# BOOT_CFG register map
Vendor: Texas Instruments
Peripheral module from a debugger description file (folder 66AK2G0x_66AK2G1x).
Registers are 32-bit, access per field, no defined reset value unless marked. A register's access mark holds for its fields unless they carry their own. Offsets are as the file gives them; lines under a group give offsets from that group; [hi:lo] are bit positions; {n}, {i} and the like mark numbered series; 'fields as' and 'values as' point back to an identical list; <NAME> marks a mode.

## BOOT_CFG
0x00 BOOTCFG_REVISION ro reset 0x4E842901
  [31:0] BOOTCFG_REV — TI internal data. Identifies revision of peripheral.
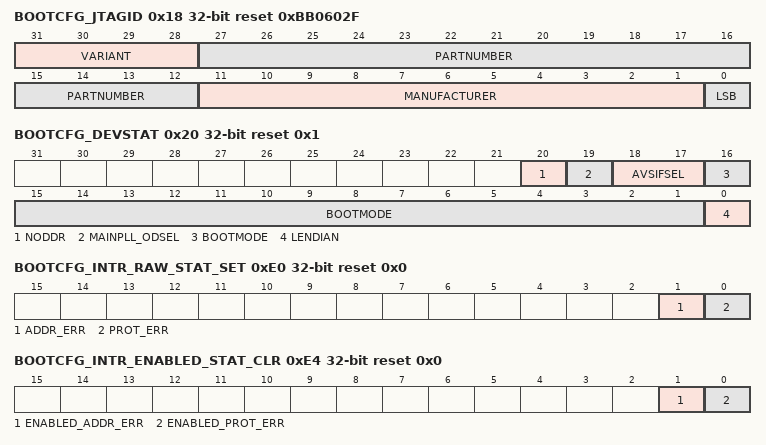
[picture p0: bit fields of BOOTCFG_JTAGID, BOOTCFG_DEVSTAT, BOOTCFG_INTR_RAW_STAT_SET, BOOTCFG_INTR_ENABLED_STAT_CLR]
0x18 BOOTCFG_JTAGID ro reset 0xBB0602F (reset mask 0xFFFFFFF)
  [31:28] VARIANT — Variant value1h for 66AK2G0x devices8h for 66AK2G1x devices
  [27:12] PARTNUMBER — Part number for boundary scan
  [11:1] MANUFACTURER — Indicates manufacture
  [0] LSB
0x20 BOOTCFG_DEVSTAT reset 0x1
  [20] NODDR ro — MSMC to EMIF control 0 - EMIF enabled, MSMC sends external traffic to DDR(normal mode) 1 - EMIF disabled, MSMC will re-direct DDR traffic toMSMC internal null end point
  [19] MAINPLL_ODSEL rw — Main PLL OUTPUT_DIVIDE (OD) selection for the Boot ROM code.
  [18:17] AVSIFSEL rw — Reserved
  [16:1] BOOTMODE rw — Boot mode selection
  [0] LENDIAN ro — Device Endian Mode. Applies to the entire device.
0x38 BOOTCFG_KICK0 rw reset 0x0
0x3C BOOTCFG_KICK1 rw reset 0x0
0x40 BOOTCFG_DSP_BOOT_ADDR0 reset 0x20B00000
  [31:10] ISTP_RST_VAL rw — DSP istp_rst_val[21:0] port value. On secure device this field is read-only by Secure Master. Emulator cannot access this in Secure mode.
0xE0 BOOTCFG_INTR_RAW_STAT_SET access not given reset 0x0
  [1] ADDR_ERR — Addressing violation error. Raw status is read. Write a 1 to set the status. Writing a 0 has no effect. (access W1toS)
  [0] PROT_ERR — Protection violation error. Raw status is read. Write a 1 to set the status. Writing a 0 has no effect. (access W1toS)
0xE4 BOOTCFG_INTR_ENABLED_STAT_CLR access not given reset 0x0
  [1] ENABLED_ADDR_ERR — Addressing violation error. Enabled status is read. Write a 1 to clear the status. Writing a 0 has no effect. (access W1toCl)
  [0] ENABLED_PROT_ERR — Protection violation error. Enabled status is read. Write a 1 to clear the status. Writing a 0 has no effect. (access W1toCl)
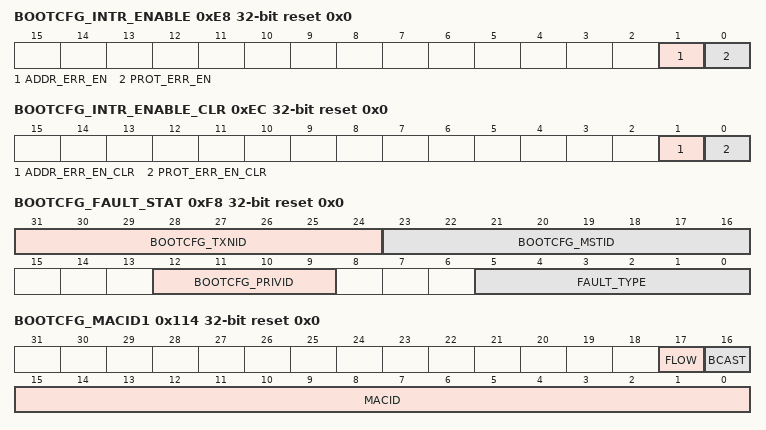
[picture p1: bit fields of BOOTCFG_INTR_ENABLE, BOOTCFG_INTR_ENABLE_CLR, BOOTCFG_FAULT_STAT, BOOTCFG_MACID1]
0xE8 BOOTCFG_INTR_ENABLE access not given reset 0x0
  [1] ADDR_ERR_EN — Addressing violation error enable. Write a 1 to set the enable. Writing a 0 has no effect. (access W1toS)
  [0] PROT_ERR_EN — Protection violation error enable. Write a 1 to set the enable. Writing a 0 has no effect. (access W1toS)
0xEC BOOTCFG_INTR_ENABLE_CLR access not given reset 0x0
  [1] ADDR_ERR_EN_CLR — Addressing violation error enable. Write a 1 to clear the enable. Writing a 0 has no effect. (access W1toCl)
  [0] PROT_ERR_EN_CLR — Protection violation error enable. Write a 1 to clear the enable. Writing a 0 has no effect. (access W1toCl)
0xF0 BOOTCFG_EOI reset 0x0
  [7:0] EOI_VECTOR rw — EOI vector value.
0xF4 BOOTCFG_FAULT_ADDR ro reset 0x0
  [31:0] FAULT_ADDR — Fault address.
0xF8 BOOTCFG_FAULT_STAT ro reset 0x0
  [31:24] BOOTCFG_TXNID — Transaction ID associated with the fault access
  [23:16] BOOTCFG_MSTID — Master ID associated with the fault access
  [12:9] BOOTCFG_PRIVID — Privilege ID associated with the fault access
  [5:0] FAULT_TYPE — Fault type. 000000b = no fault 000001b = user execute fault 000010b = user write fault 000100b = user read fault 001000b = supervisor execute fault 010000b = supervisor write fault 100000b = supervisor read fault
0xFC BOOTCFG_FAULT_CLR access not given reset 0x0
  [0] FAULT_CLR — Fault clear. Writing a 1 clears the current fault. Writing a 0 has no effect. (access W1toCl)
0x110 BOOTCFG_MACID0 ro
  [31:0] MACID — MAC ID, lower 32 bits
0x114 BOOTCFG_MACID1 ro reset 0x0 (reset mask 0xFFFF0000)
  [17] FLOW — MAC Flow Control
  [16] BCAST — Default m/b-cast reception
  [15:0] MACID — MAC ID, upper 16 bits
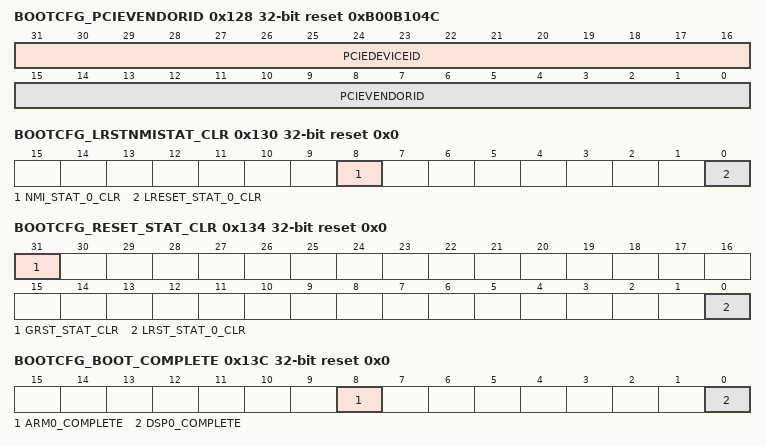
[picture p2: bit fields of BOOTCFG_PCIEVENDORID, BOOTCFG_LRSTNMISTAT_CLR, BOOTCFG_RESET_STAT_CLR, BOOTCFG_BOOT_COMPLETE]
0x128 BOOTCFG_PCIEVENDORID rw reset 0xB00B104C
  [31:16] PCIEDEVICEID
  [15:0] PCIEVENDORID — TI Vendor ID
0x130 BOOTCFG_LRSTNMISTAT_CLR access not given reset 0x0
  [8] NMI_STAT_0_CLR — C66x core 0 NMI pin clear (access RWtoPH)
  [0] LRESET_STAT_0_CLR — C66x core 0 local reset pin clear (access RWtoPH)
0x134 BOOTCFG_RESET_STAT_CLR access not given reset 0x0
  [31] GRST_STAT_CLR — Global reset clear (access RWtoPH)
  [0] LRST_STAT_0_CLR — C66x core 0 local reset clear (access RWtoPH)
0x13C BOOTCFG_BOOT_COMPLETE access not given reset 0x0
  [8] ARM0_COMPLETE — A15 core 0 ROM boot status (access RW1toS)
  [0] DSP0_COMPLETE — C66x core 0 ROM boot status (access RW1toS)
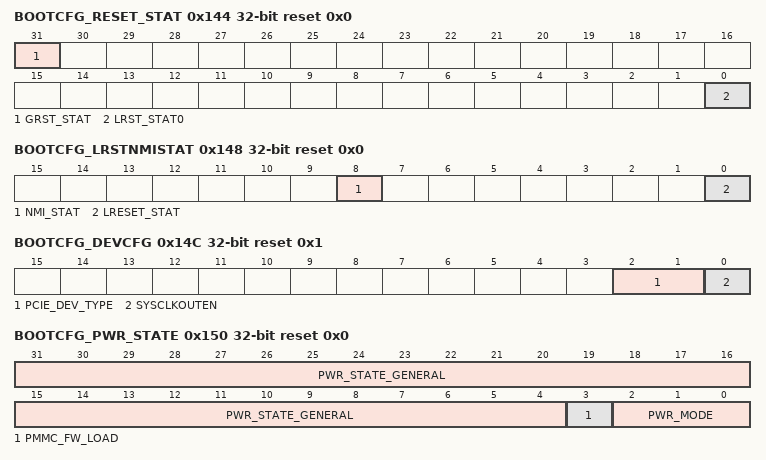
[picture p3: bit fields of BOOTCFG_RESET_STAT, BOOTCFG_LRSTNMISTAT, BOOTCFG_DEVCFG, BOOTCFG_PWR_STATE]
0x144 BOOTCFG_RESET_STAT ro reset 0x0
  [31] GRST_STAT — Global reset status
  [0] LRST_STAT0 — C66x core 0 local reset status
0x148 BOOTCFG_LRSTNMISTAT ro reset 0x0
  [8] NMI_STAT — C66x core 0 NMI pin status
  [0] LRESET_STAT — C66x core 0 local reset pin status
0x14C BOOTCFG_DEVCFG reset 0x1
  [2:1] PCIE_DEV_TYPE rw — PCIE device type 0h = Endpoint mode 1h = Legacy Endpoint mode 2h = Rootcomplex mode
  [0] SYSCLKOUTEN rw — SYSCLKOUT enable
0x150 BOOTCFG_PWR_STATE rw reset 0x0
  [31:4] PWR_STATE_GENERAL — General purpose register, allocated for software usage
  [3] PMMC_FW_LOAD — Indicates whether PMMC firmware is loaded by host processor (A15 or DSP) or not
  [2:0] PWR_MODE — Indicates device power mode
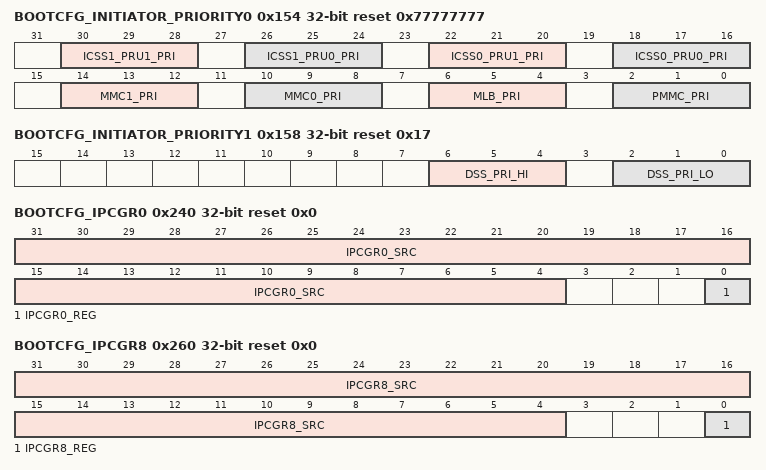
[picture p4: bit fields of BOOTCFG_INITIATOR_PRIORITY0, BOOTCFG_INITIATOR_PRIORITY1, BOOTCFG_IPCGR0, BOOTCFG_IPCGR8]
0x154 BOOTCFG_INITIATOR_PRIORITY0 reset 0x77777777
  [30:28] ICSS1_PRU1_PRI rw — ICSS1 PRU1 master port priority
  [26:24] ICSS1_PRU0_PRI rw — ICSS1 PRU0 master port priority
  [22:20] ICSS0_PRU1_PRI rw — ICSS0 PRU1 master port priority
  [18:16] ICSS0_PRU0_PRI rw — ICSS0 PRU0 master port priority
  [14:12] MMC1_PRI rw — MMC1 master port priority
  [10:8] MMC0_PRI rw — MMC0 master port priority
  [6:4] MLB_PRI rw — MLB master port priority
  [2:0] PMMC_PRI rw — PMMC master port priority
0x158 BOOTCFG_INITIATOR_PRIORITY1 reset 0x17
  [6:4] DSS_PRI_HI rw — DSS master port priority for high priority access (when MFLAG = 1)
  [2:0] DSS_PRI_LO rw — DSS master port priority for low priority access (when MFLAG = 0)
0x200 BOOTCFG_NMIGR0 access not given reset 0x0
  [0] NMIGR0_REG — Reads return 0 (access RWtoPH)
0x240 BOOTCFG_IPCGR0 access not given reset 0x0
  [31:4] IPCGR0_SRC — Reads return current value of internal register bit (access RW1toS)
  [0] IPCGR0_REG — Reads return 0 (access RWtoPH)
0x260 BOOTCFG_IPCGR8 access not given reset 0x0
  [31:4] IPCGR8_SRC — Reads return current value of internal register bit (access RW1toS)
  [0] IPCGR8_REG — Reads return 0 (access RWtoPH)
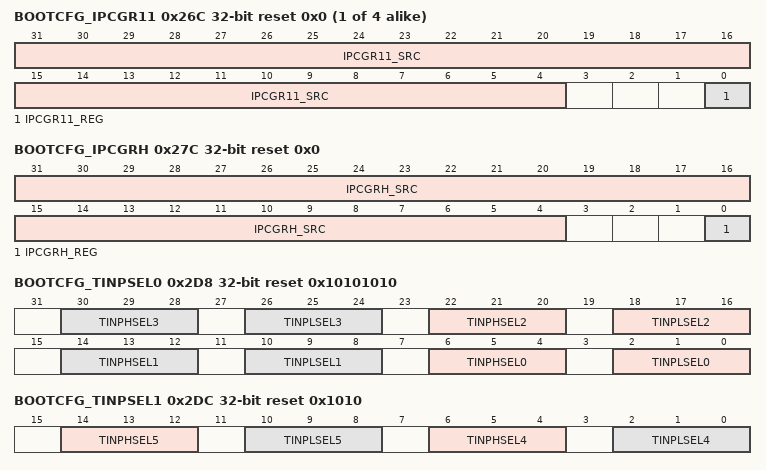
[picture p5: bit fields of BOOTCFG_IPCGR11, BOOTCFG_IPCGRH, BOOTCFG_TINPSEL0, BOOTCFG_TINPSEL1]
{0x240+4i} BOOTCFG_IPCGR{i} access not given reset 0x0 (i=11..14)
  [31:4] IPCGR{i}_SRC — Reads return current value of internal register bit (access RW1toS)
  [0] IPCGR{i}_REG — Reads return 0 (access RWtoPH)
0x27C BOOTCFG_IPCGRH access not given reset 0x0
  [31:4] IPCGRH_SRC — Reads return current value of internal register bit (access RW1toS)
  [0] IPCGRH_REG — Reads return 0 (access RWtoPH)
0x280 BOOTCFG_IPCAR0 access not given reset 0x0
  [31:4] IPCGR0_SRC_CLR — Reads return current value of internal register bit (access RW1toCl)
0x2A0 BOOTCFG_IPCAR8 access not given reset 0x0
  [31:4] IPCGR8_SRC_CLR — Reads return current value of internal register bit (access RW1toCl)
{0x280+4i} BOOTCFG_IPCAR{i} access not given reset 0x0 (i=11..14)
  [31:4] IPCGR{i}_SRC_CLR — Reads return current value of internal register bit (access RW1toC)
0x2BC BOOTCFG_IPCARH access not given reset 0x0
  [31:4] IPCGRH_SRC_CLR — Reads return current value of internal register bit (access RW1toC)
0x2D8 BOOTCFG_TINPSEL0 reset 0x10101010
  [8n+6:8n+4] TINPHSEL{n} rw (n=0..3) — Input select for TIMER_{n} high 0h = TIMI0 1h = TIMI1
  [8n+2:8n] TINPLSEL{n} rw (n=0..3) — Input select for TIMER_{n} low 0h = TIMI0 1h = TIMI1
0x2DC BOOTCFG_TINPSEL1 reset 0x1010
  [14:12] TINPHSEL5 rw — Input select for TIMER_5 high 0h = TIMI0 1h = TIMI1
  [10:8] TINPLSEL5 rw — Input select for TIMER_5 low 0h = TIMI0 1h = TIMI1
  [6:4] TINPHSEL4 rw — Input select for TIMER_4 high 0h = TIMI0 1h = TIMI1
  [2:0] TINPLSEL4 rw — Input select for TIMER_4 low 0h = TIMI0 1h = TIMI1
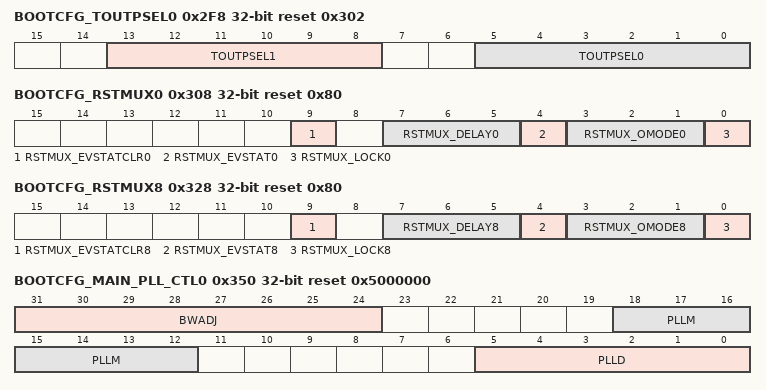
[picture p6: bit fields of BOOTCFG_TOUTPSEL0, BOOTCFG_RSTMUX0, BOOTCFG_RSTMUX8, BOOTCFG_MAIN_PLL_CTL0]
0x2F8 BOOTCFG_TOUTPSEL0 reset 0x302
  [13:8] TOUTPSEL1 rw — Output select for TIMO1 0h = TOUTL0 1h = TOUTH0 2h = TOUTL1 3h = TOUTH1 4h = TOUTL2 5h = TOUTH2 6h = TOUTL3 7h = TOUTH3 8h = TOUTL4 9h = TOUTH4 Ah = TOUTL5 Bh = TOUTH5
  [5:0] TOUTPSEL0 rw — Output select for TIMO0 0h = TOUTL0 1h = TOUTH0 2h = TOUTL1 3h = TOUTH1 4h = TOUTL2 5h = TOUTH2 6h = TOUTL3 7h = TOUTH3 8h = TOUTL4 9h = TOUTH4 Ah = TOUTL5 Bh = TOUTH5
0x308 BOOTCFG_RSTMUX0 access not given reset 0x80
  [9] RSTMUX_EVSTATCLR0 — Clear event status (access RWtoPH)
  [7:5] RSTMUX_DELAY0 rw — Delay cycles between NMI and local reset to C66x core incase of C66x WD timer, or delay between GIC interrupt and device reset in case of A15 WD timer
  [4] RSTMUX_EVSTAT0 ro — Event status
  [3:1] RSTMUX_OMODE0 rw — Watchdog timer event operation mode
  [0] RSTMUX_LOCK0 rw — Lock register fields
0x328 BOOTCFG_RSTMUX8 access not given reset 0x80
  [9] RSTMUX_EVSTATCLR8 — Clear event status (access RWtoPH)
  [7:5] RSTMUX_DELAY8 rw — Delay cycles between NMI and local reset to C66x core incase of C66x WD timer, or delay between GIC interrupt and device reset in case of A15 WD timer
  [4] RSTMUX_EVSTAT8 ro — Event status
  [3:1] RSTMUX_OMODE8 rw — Watchdog timer event operation mode
  [0] RSTMUX_LOCK8 rw — Lock register fields
0x350 BOOTCFG_MAIN_PLL_CTL0 reset 0x5000000
  [31:24] BWADJ rw — 8-bit LSB of a 12-bit BWADJ field that selects the values for the loop bandwidth adjustment. BWADJ[7-0] is controlled from this register and BWADJ[11-8] is controlled from
  [18:12] PLLM rw — 7-bit MSB of a 13-bit PLLM field that selects the values for the multiplication factor. PLLM field is loaded with the multiply factor minus 1. The PLLM[5-0] bits of the multiplier are controlled by the PLLM register inside the PLL Controller and the PLLM[12-6] bits are controlled by this register. This field should be written just before writing to PLLM[5-0] bits of the PLLM register to have the complete 13-bit value latched when the GO operation is initiated in the PLL Controller
  [5:0] PLLD rw — A 6-bit field that selects the values for the reference divider. PLLD field is loaded with reference divider value minus 1
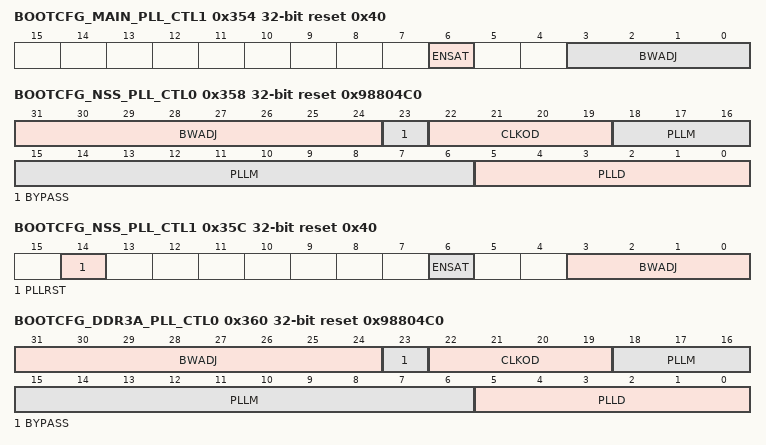
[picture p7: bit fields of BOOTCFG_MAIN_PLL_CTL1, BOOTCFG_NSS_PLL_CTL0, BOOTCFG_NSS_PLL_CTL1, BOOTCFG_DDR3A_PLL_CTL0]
0x354 BOOTCFG_MAIN_PLL_CTL1 reset 0x40
  [6] ENSAT rw — Enables saturation behavior, needs to be set to 1 for proper PLLoperation
  [3:0] BWADJ rw — 4-bit MSB of a 12-bit BWADJ field that selects the values for the loop bandwidth adjustment. BWADJ[7-0] is controlled from MAINPLLCTL0 register and BWADJ[11-8] is controlled from this register. BWADJ[11-0] should be programmed to a value equal to half of PLLM[12-0] value (round down if PLLM has an odd value).
0x358 BOOTCFG_NSS_PLL_CTL0 rw reset 0x98804C0
  [31:24] BWADJ — 8-bit LSB of a 12-bit BWADJ field that selects the values for the loop bandwidth adjustment. BWADJ[7-0] is controlled from this register and BWADJ[11-8] is controlled from
  [23] BYPASS — Enable bypass mode
  [22:19] CLKOD — PLL output divider (post VCO), supported value = 1 (i.e. divide-by-2)
  [18:6] PLLM — A 13-bit field that selects the values for the multiplication factor. PLLM field is loaded with the multiply factor minus 1
  [5:0] PLLD — A 6-bit field that selects the values for the reference divider. PLLD field is loaded with reference divide value minus 1
0x35C BOOTCFG_NSS_PLL_CTL1 reset 0x40
  [14] PLLRST rw — PLL reset bit
  [6] ENSAT rw — Enables saturation behavior, needs to be set to 1 for proper PLL operation
  [3:0] BWADJ rw — 4-bit MSB of a 12-bit BWADJ field that selects the values for the loop bandwidth adjustment. BWADJ[7-0] is controlled from
0x360 BOOTCFG_DDR3A_PLL_CTL0 rw reset 0x98804C0
  fields as BOOTCFG_NSS_PLL_CTL0
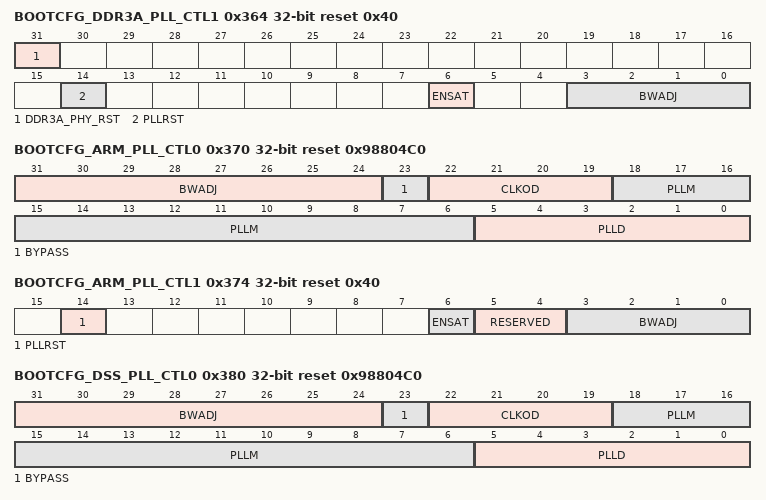
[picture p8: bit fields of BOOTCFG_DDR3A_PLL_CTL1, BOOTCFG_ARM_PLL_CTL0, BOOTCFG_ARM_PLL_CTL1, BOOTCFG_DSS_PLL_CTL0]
0x364 BOOTCFG_DDR3A_PLL_CTL1 reset 0x40
  [31] DDR3A_PHY_RST rw — DDR3 PHY reset control For more information, see
  [14] PLLRST rw — PLL reset bit
  [6] ENSAT rw — Enables saturation behavior, needs to be set to 1 for proper PLL operation
  [3:0] BWADJ rw — 4-bit MSB of a 12-bit BWADJ field that selects the values for the loop bandwidth adjustment. BWADJ[7-0] is controlled from
0x370 BOOTCFG_ARM_PLL_CTL0 rw reset 0x98804C0
  fields as BOOTCFG_NSS_PLL_CTL0
0x374 BOOTCFG_ARM_PLL_CTL1 reset 0x40
  [14] PLLRST rw — PLL reset bit
  [6] ENSAT rw — Enables saturation behavior, needs to be set to 1 for proper PLL operation
  [5:4] RESERVED ro — Enables fast locking circuit
  [3:0] BWADJ rw — 4-bit MSB of a 12-bit BWADJ field that selects the values for the loop bandwidth adjustment. BWADJ[7-0] is controlled from
0x380 BOOTCFG_DSS_PLL_CTL0 rw reset 0x98804C0
  fields as BOOTCFG_NSS_PLL_CTL0
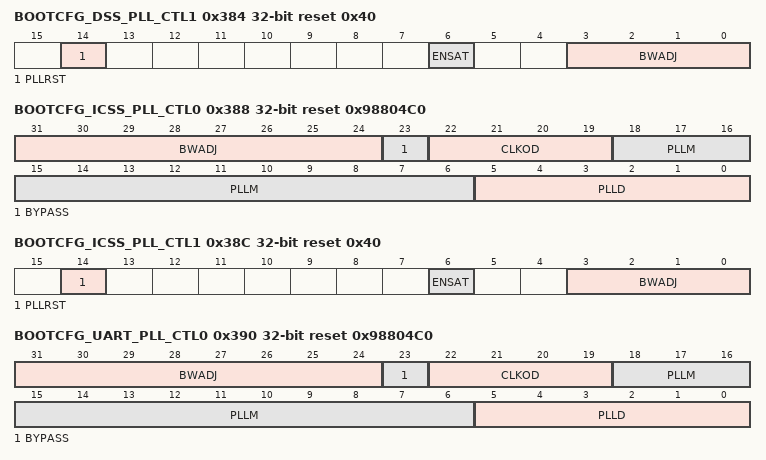
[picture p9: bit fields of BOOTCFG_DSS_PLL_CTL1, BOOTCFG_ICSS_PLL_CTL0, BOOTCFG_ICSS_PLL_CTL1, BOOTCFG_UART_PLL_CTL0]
0x384 BOOTCFG_DSS_PLL_CTL1 reset 0x40
  fields as BOOTCFG_NSS_PLL_CTL1
0x388 BOOTCFG_ICSS_PLL_CTL0 rw reset 0x98804C0
  fields as BOOTCFG_NSS_PLL_CTL0
0x38C BOOTCFG_ICSS_PLL_CTL1 reset 0x40
  fields as BOOTCFG_NSS_PLL_CTL1
0x390 BOOTCFG_UART_PLL_CTL0 rw reset 0x98804C0
  fields as BOOTCFG_NSS_PLL_CTL0
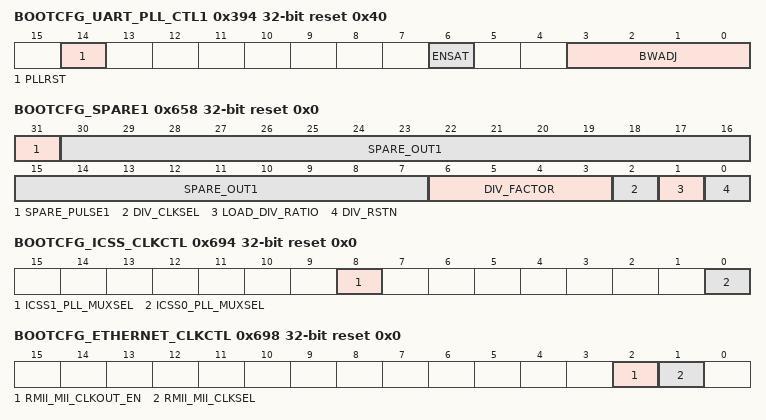
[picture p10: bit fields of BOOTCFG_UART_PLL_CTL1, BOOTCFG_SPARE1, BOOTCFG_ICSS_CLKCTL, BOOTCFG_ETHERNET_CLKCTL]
0x394 BOOTCFG_UART_PLL_CTL1 reset 0x40
  fields as BOOTCFG_NSS_PLL_CTL1
0x658 BOOTCFG_SPARE1 access not given reset 0x0
  [31] SPARE_PULSE1 — When this bit is set to 1, it generates a pulse for one BOOT_CFG_VBUS_CLK clock period. Read return zero. (access WPH)
  [30:7] SPARE_OUT1 rw — Reserved.
  [6:3] DIV_FACTOR rw — DSS divider value.Clock is divided by DIV_FACTOR+1.
  [2] DIV_CLKSEL rw — DSS divided clock select.0 - Use DSS clock1 - Use divided DSS clock
  [1] LOAD_DIV_RATIO rw — DSS divide value load.Pulse this bit by writing 1 followed by a 0 to load the DIV_FACTOR and start the divider.
  [0] DIV_RSTN rw — DSS divider reset.Clear this bit to 0 before changing the DIV_FACTOR and set to 1 after DIV_FACTOR is programmed.
0x690 BOOTCFG_DDR_CLKCTL reset 0x0
  [0] DDR_CLK_MUXSEL rw — DDR PLL Reference Clock Source 0 - Select HF Oscillator (when SYSCLKSEL pin is low) or external SYSCLK_P/N input (when SYSCLKSEL pin is high) 1 - Select external DDR_CLK_P/N input
0x694 BOOTCFG_ICSS_CLKCTL reset 0x0
  [8] ICSS1_PLL_MUXSEL rw — ICSS1 Core Clock Source. 0 = Selects ICSS PLL output 1 = Selects NSS PLL output
  [0] ICSS0_PLL_MUXSEL rw — ICSS0 Core Clock Source. 0 = Selects ICSS PLL output 1 = Selects NSS PLL output
0x698 BOOTCFG_ETHERNET_CLKCTL reset 0x0
  [2] RMII_MII_CLKOUT_EN rw — BOOTROM code will set this bit based on the BOOTMODE selection 0 - CLKOUT pin is disabled 1 - CLKOUT pin is enabled
  [1] RMII_MII_CLKSEL rw — BOOTROM code will set this bit based on the BOOTMODE selection 0 - RMII_CLK will drive the CLKOUT pin 1 - MII_CLK will drive the CLKOUT pin
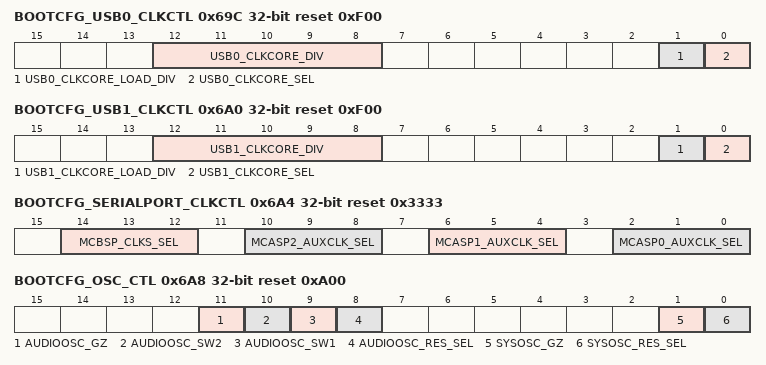
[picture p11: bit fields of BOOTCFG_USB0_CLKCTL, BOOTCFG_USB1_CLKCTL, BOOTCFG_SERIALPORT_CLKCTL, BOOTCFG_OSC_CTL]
0x69C BOOTCFG_USB0_CLKCTL reset 0xF00
  [12:8] USB0_CLKCORE_DIV rw — USB0 Core Clock Divider Value. This field must be set to &lt;divider value&gt; - 1.
  [1] USB0_CLKCORE_LOAD_DIV rw — USB0 Core Clock Load Divider Control
  [0] USB0_CLKCORE_SEL rw — USB0 Core Clock Source
0x6A0 BOOTCFG_USB1_CLKCTL reset 0xF00
  [12:8] USB1_CLKCORE_DIV rw — USB1 Core Clock Divider Value. This field must be set to &lt;divider value&gt; - 1.
  [1] USB1_CLKCORE_LOAD_DIV rw — USB1 Core Clock Load Divider Control
  [0] USB1_CLKCORE_SEL rw — USB1 Core Clock Source
0x6A4 BOOTCFG_SERIALPORT_CLKCTL reset 0x3333
  [14:12] MCBSP_CLKS_SEL rw — McBSP CLKS Source Selection 000b - AUDIO_OSCCLK 001b - MLB_IO_CLK 010b - MLBP_IO_CLK 011b - SYS_OSCCLK 100b - XREFCLK (external pin) 101b - UART_PLL/4 All others are reserved.
  [10:8] MCASP2_AUXCLK_SEL rw — McASP2 AUXCLK Source Selection 000b - AUDIO_OSCCLK 001b - MLB_IO_CLK 010b - MLBP_IO_CLK 011b - SYS_OSCCLK 100b - XREFCLK (external pin) 101b - UART_PLL/4 All others are reserved.
  [6:4] MCASP1_AUXCLK_SEL rw — McASP1 AUXCLK Source Selection 000b - AUDIO_OSCCLK 001b - MLB_IO_CLK 010b - MLBP_IO_CLK 011b - SYS_OSCCLK 100b - XREFCLK (external pin) 101b - UART_PLL/4 All others are reserved.
  [2:0] MCASP0_AUXCLK_SEL rw — McASP0 AUXCLK Source Selection 000b - AUDIO_OSCCLK 001b - MLB_IO_CLK 010b - MLBP_IO_CLK 011b - SYS_OSCCLK 100b - XREFCLK (external pin) 101b - UART_PLL/4 All others are reserved.
0x6A8 BOOTCFG_OSC_CTL reset 0xA00
  [11] AUDIOOSC_GZ rw — Audio Oscillator enable control 0 - Audio Oscillator is enabled 1 - Audio Oscillator is disabled
  [10] AUDIOOSC_SW2 rw — Selects the frequency range of the Audio oscillator SW2:SW1 control bits
  [9] AUDIOOSC_SW1 rw — Selects the frequency range of the Audio oscillator SW2:SW1 control bits
  [8] AUDIOOSC_RES_SEL rw — Audio Oscillator Resistor
  [1] SYSOSC_GZ rw — System Oscillator enable control 0 - System Oscillator is enabled 1 - System Oscillator is disabled
  [0] SYSOSC_RES_SEL rw — System Oscillator Resistor
0x6AC BOOTCFG_PCIE_CLKCTL reset 0x0
  [2:0] PCIE_REFCLK_INPUT_SEL rw — PCIE PHY Reference Clock Selection
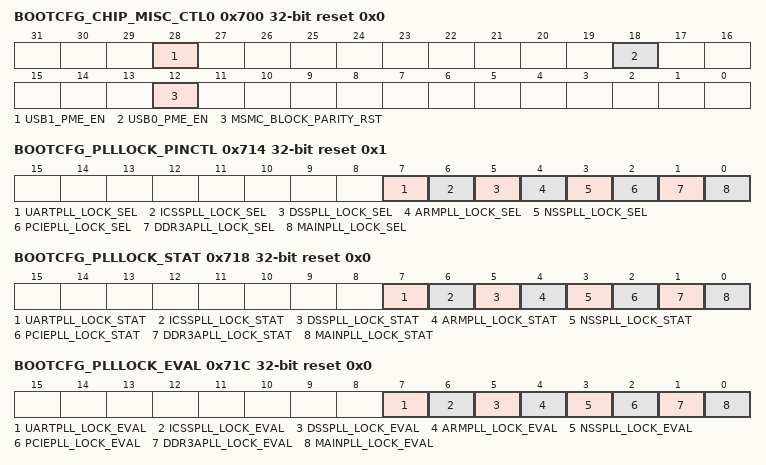
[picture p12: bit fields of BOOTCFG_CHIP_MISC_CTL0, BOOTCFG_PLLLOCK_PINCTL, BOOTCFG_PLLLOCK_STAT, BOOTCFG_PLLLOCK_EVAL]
0x700 BOOTCFG_CHIP_MISC_CTL0 reset 0x0
  [28] USB1_PME_EN rw — Enable wakeup event generation from USB1
  [18] USB0_PME_EN rw — Enable wakeup event generation from USB0
  [12] MSMC_BLOCK_PARITY_RST rw — Controls MSMC parity RAM reset on device reset
0x710 BOOTCFG_SYSENDSTAT ro reset 0x1
  [0] SYSENDSTAT — System Endian Status 0h - Reserved 1h - System is in Little Endian mode
0x714 BOOTCFG_PLLLOCK_PINCTL reset 0x1
  [7] UARTPLL_LOCK_SEL rw — UART PLL lock select
  [6] ICSSPLL_LOCK_SEL rw — ICSS PLL lock select
  [5] DSSPLL_LOCK_SEL rw — DSS PLL lock select
  [4] ARMPLL_LOCK_SEL rw — ARM PLL lock select
  [3] NSSPLL_LOCK_SEL rw — NSS PLL lock select
  [2] PCIEPLL_LOCK_SEL rw — PCIE PHY PLL lock select
  [1] DDR3APLL_LOCK_SEL rw — DDR3A PLL lock select
  [0] MAINPLL_LOCK_SEL rw — Main PLL lock select
0x718 BOOTCFG_PLLLOCK_STAT ro reset 0x0
  [7] UARTPLL_LOCK_STAT — 0 - PLL LOCK is de-asserted (either initial state or lock was lost)
  [6] ICSSPLL_LOCK_STAT — 0 - PLL LOCK is de-asserted (either initial state or lock was lost)
  [5] DSSPLL_LOCK_STAT — 0 - PLL LOCK is de-asserted (either initial state or lock was lost)
  [4] ARMPLL_LOCK_STAT — 0 - PLL LOCK is de-asserted (either initial state or lock was lost)
  [3] NSSPLL_LOCK_STAT — 0 - PLL LOCK is de-asserted (either initial state or lock was lost)
  [2] PCIEPLL_LOCK_STAT — 0 - PLL LOCK is de-asserted (either initial state or lock was lost)
  [1] DDR3APLL_LOCK_STAT — 0 - PLL LOCK is de-asserted (either initial state or lock was lost)
  [0] MAINPLL_LOCK_STAT — 0 - PLL LOCK is de-asserted (either initial state or lock was lost)
0x71C BOOTCFG_PLLLOCK_EVAL reset 0x0
  [7] UARTPLL_LOCK_EVAL rw — Write 0 - No action
  [6] ICSSPLL_LOCK_EVAL rw — Write 0 - No action
  [5] DSSPLL_LOCK_EVAL rw — Write 0 - No action
  [4] ARMPLL_LOCK_EVAL rw — Write 0 - No action
  [3] NSSPLL_LOCK_EVAL rw — Write 0 - No action
  [2] PCIEPLL_LOCK_EVAL rw — Write 0 - No action
  [1] DDR3APLL_LOCK_EVAL rw — Write 0 - No action
  [0] MAINPLL_LOCK_EVAL rw — Write 0 - No action
0x720 BOOTCFG_PLLCLKSEL_STAT ro reset 0x0
  [0] SYSCLKSEL_STAT — Status of SYSCLK PLL mux selection 0 - HF Oscillator drives the SYSCLK as reference input clock to the PLLs 1 - SYSCLK_P and SYSCLK_N pins drive the reference input clock to the PLLs
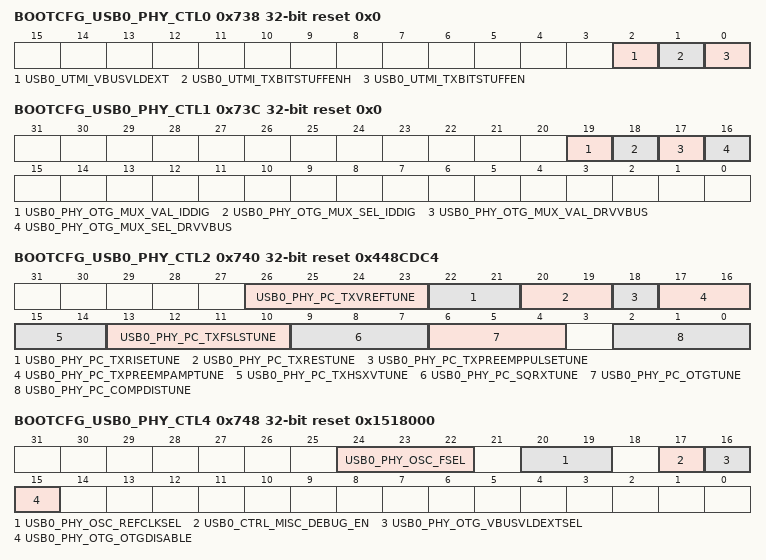
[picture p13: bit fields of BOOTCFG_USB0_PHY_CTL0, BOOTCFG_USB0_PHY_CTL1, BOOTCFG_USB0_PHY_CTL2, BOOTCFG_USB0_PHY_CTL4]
0x738 BOOTCFG_USB0_PHY_CTL0 reset 0x0
  [2] USB0_UTMI_VBUSVLDEXT rw — External VBUS Valid Indicator. This signal is valid in Device mode and only when the VBUSVLDEXTSEL signal is set to 1. VBUSVLDEXT indicates whether the VBUS signal on the USB cable is valid. In addition, VBUSVLDEXT enables the pull-up resistor on the D+ line. 0: The VBUS signal is not valid, and the pull-up resistor on D+ is disabled. 1: The VBUS signal is valid, and the pull-up resistor on D+ is enabled.
  [1] USB0_UTMI_TXBITSTUFFENH rw — High-Byte Transmit Bit-Stuffing Enable. This controller signal controls bit stuffing on DATAINH(7:0) when OPMODE(1:0) = 3h. 0: Bit stuffing is disabled. 1: Bit stuffing is enabled.
  [0] USB0_UTMI_TXBITSTUFFEN rw — Low-Byte Transmit Bit-Stuffing Enable. This controller signal controls bit stuffing on DATAIN(7:0) when OPMODE(1:0) = 3h. 0: Bit stuffing is disabled. 1: Bit stuffing is enabled.
0x73C BOOTCFG_USB0_PHY_CTL1 reset 0x0
  [19] USB0_PHY_OTG_MUX_VAL_IDDIG rw — Mux value for iddig if PHY_OTG_MUX_SEL_IDDIG=1
  [18] USB0_PHY_OTG_MUX_SEL_IDDIG rw — Mux select for iddig 0: Driven from PHY 1: Use PHY_OTG_MUX_SEL_IDDIG
  [17] USB0_PHY_OTG_MUX_VAL_DRVVBUS rw — Mux value for drvvbus if PHY_OTG_MUX_SEL_DRVVBUS=1
  [16] USB0_PHY_OTG_MUX_SEL_DRVVBUS rw — Mux select for drvvbus 0: Driven from controller 1: UsePHY_OTG_MUX_VAL_DRVVBUS
0x740 BOOTCFG_USB0_PHY_CTL2 reset 0x448CDC4
  [26:23] USB0_PHY_PC_TXVREFTUNE rw — HS DC Voltage Level Adjustment. This bus adjusts the high-speed DC level voltage. 0000: -10% 0001: -8.75% 0010: -7.5% 0011: -6.25% 0100: -5% 0101: -3.75% 0110: -2.5% 0111: -1.25% 1000: Design default 1001: +1.25% 1010: +2.5% 1011: +3.75% 1100: +5% 1101: +6.25% 1110: +7.5% 1111: +8.75%
  [22:21] USB0_PHY_PC_TXRISETUNE rw — HS Transmitter Rise/Fail Time Adjustment. This bus adjusts the rise/fail times of the high-speed waveform. 00: +20% 01: +15% 10: Design default 11: -10%
  [20:19] USB0_PHY_PC_TXRESTUNE rw — USB Source impedance Adjustment. In some applications, there can be significant series resistance on the D+ and D- paths between the transceiver and cable. This bus adjusts the driver source impedance to compensate for added series resistance on the USB. Note: Any setting other than the default can result in source impedance variation across process, voltage, and temperature conditions that does not meet USB 2.0 specification limits. 00: Source impedance is increased by approximately 1.5 ohm 01: Design default 10: Source impedance is decreased by approximately 2 ohm 11: Source impedance is decreased by approximately 4 ohm
  [18] USB0_PHY_PC_TXPREEMPPULSETUNE rw — HS Transmitter Pre-Emphasis Duration Control. This signal controls the duration for which the HS pre-emphasis current is sourced onto DP or DM. The HS Transmitter pre-emphasis duration is defined in terms of unit amounts. One unit of pre-emphasis duration is approximately 580 ps and is defined as 1X pre-emphasis duration. This signal is valid only if either TXPREEMPAMPTUNE0 or TXPREEMPAMPTUNE2 is set to 1. 0 (design default): 2X, long pre-emphasis current duration 1: 1X, short pre-emphasis current duration
  [17:16] USB0_PHY_PC_TXPREEMPAMPTUNE rw — HS Transmitter Pre-Emphasis Current Control. This signal controls the amount of current sourced to DP and after a J-to-K or K-to-J transition. The HS Transmitter pre-emphasis current is defined in terms of unit amounts. One unit amount is approximately 600 uA and is defined as 1X pre-emphasis current. 00 (design default): HS Transmitter pre-emphasis is disabled. 01: HS Transmitter pre-emphasis circuit sources 1X pre-emphasis current. 10: HS Transmitter pre-emphasis circuit sources 2X pre-emphasis current. 11: HS Transmitter pre-emphasis circuit sources 3X pre-emphasis current. If these signals are not used, set them to 00b.
  [15:14] USB0_PHY_PC_TXHSXVTUNE rw — Transmitter High-Speed Crossover Adjustment. This bus adjusts the voltage at which the DP and DM signals cross while transmitting in HS mode. 00: Reserved 01: -15mV 10: +15mV 11: Default setting
  [13:10] USB0_PHY_PC_TXFSLSTUNE rw — FS/LS Source impedance Adjustment. This bus adjusts the low- and full-speed single-ended source impedance while driving high.The following adjustment values are based on nominal process, voltage, and temperature. 0000: +5% 0001: +2.5% 0011: Design default 0111: -2.5% 1111: -5% All other bit settings are reserved.
  [9:7] USB0_PHY_PC_SQRXTUNE rw — Squelch Threshold Adjustment. This bus adjusts the voltage level for the threshold used to detect valid high-speed data. 000: +15% 001: +10% 010: +5% 011: Design default 100: -5% 101: -10% 110: -15% 111: -20%
  [6:4] USB0_PHY_PC_OTGTUNE rw — VBUS Valid Threshold Adjustment. This bus adjusts the voltage level for the VBUS valid threshold. 000: -12% 001: -9% 010: -6% 011: -3% 100: Design default 101: +3% 110: +6% 111: +9%
  [2:0] USB0_PHY_PC_COMPDISTUNE rw — Disconnect Threshold Adjustment. This bus adjusts the voltage level for the threshold used to detect a disconnect event at the host. 000: -6% 001: -4.5% 010: -3% 011: -1.5% 100: Design default 101: +1.5% 110: +3% 111: +4.5%
0x748 BOOTCFG_USB0_PHY_CTL4 reset 0x1518000
  [24:22] USB0_PHY_OSC_FSEL rw — Reference Clock Frequency Select. Selects the USB2.0 picoPHY reference clock frequency. 000: Reserved 001: Reserved 010: 12MHz 011: 19.2MHz 100: Reserved 101: 24MHz (default) 110: Reserved 111: 50MHz
  [20:19] USB0_PHY_OSC_REFCLKSEL rw — Reference Clock Select for PLL Block. This signal selects the reference clock source for the PLL Block. 00: Crystal 01: External Clock 10: Internal Clock (default) 11: Reserved
  [17] USB0_CTRL_MISC_DEBUG_EN rw — Enable CTL_MISC_DEBUG_DATA 0: disable 1: enable
  [16] USB0_PHY_OTG_VBUSVLDEXTSEL rw — External VBUS Valid Select. This signal selects either the VBUSVLDEXT input or the internal Session Valid comparator to generate the OTGSESSVLD output. To avoid potential glitches in DP, VBUSVLDEXTSEL must be static prior to a power-on reset and remain static during normal operation. The OTGSESSVLD signal, in conjunction with XCVRSEL(1:0), OPMODE(1:0), TERMSEL, DPPULLDOWN, and DMPULLDOWN, control the DP pull-up resistor. If VBUSVLDEXT and the internal Session Valid comparator output are asserted, and VBUSEXTSEL changes, it is possible for OTGSESSVLD to glitch low, causing the DP resistor to be temporarily disabled. 0: The internal Session Valid comparator is used to generate OTGSESSVLD and assert the DP pull-up resistor. 1: The VBUSVLDEXT input is used to generate OTGSESSVLD and assert the DP pull-up resistor.
  [15] USB0_PHY_OTG_OTGDISABLE rw — OTG Block Disable. This signal powers down the VBUS Valid comparator, but not the Session Valid comparator, ADP probe and sense comparators, nor the ID detection circuitry. To save power, if the application does not use the OTG function, this input can be set high. 0: The OTG block is powered up. 1: The OTG block is powered down.
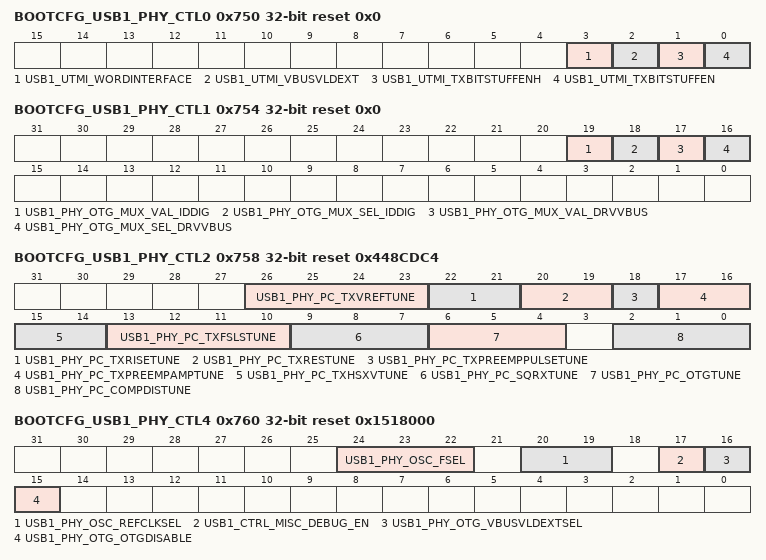
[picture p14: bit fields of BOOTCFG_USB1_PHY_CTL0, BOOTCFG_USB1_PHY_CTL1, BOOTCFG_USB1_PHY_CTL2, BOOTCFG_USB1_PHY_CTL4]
0x750 BOOTCFG_USB1_PHY_CTL0 reset 0x0
  [3] USB1_UTMI_WORDINTERFACE rw
  [2] USB1_UTMI_VBUSVLDEXT rw — External VBUS Valid Indicator. This signal is valid in Device mode and only when the VBUSVLDEXTSEL signal is set to 1. VBUSVLDEXT indicates whether the VBUS signal on the USB cable is valid. In addition, VBUSVLDEXT enables the pull-up resistor on the D+ line. 0: The VBUS signal is not valid, and the pull-up resistor on D+ is disabled. 1: The VBUS signal is valid, and the pull-up resistor on D+ is enabled.
  [1] USB1_UTMI_TXBITSTUFFENH rw — High-Byte Transmit Bit-Stuffing Enable. This controller signal controls bit stuffing on DATAINH(7:0) when OPMODE(1:0) = 3h. 0: Bit stuffing is disabled. 1: Bit stuffing is enabled.
  [0] USB1_UTMI_TXBITSTUFFEN rw — Low-Byte Transmit Bit-Stuffing Enable. This controller signal controls bit stuffing on DATAIN(7:0) when OPMODE(1:0) = 3h. 0: Bit stuffing is disabled. 1: Bit stuffing is enabled.
0x754 BOOTCFG_USB1_PHY_CTL1 reset 0x0
  [19] USB1_PHY_OTG_MUX_VAL_IDDIG rw — Mux value for iddig if PHY_OTG_MUX_SEL_IDDIG=1
  [18] USB1_PHY_OTG_MUX_SEL_IDDIG rw — Mux select for iddig 0: Driven from PHY 1: Use PHY_OTG_MUX_SEL_IDDIG
  [17] USB1_PHY_OTG_MUX_VAL_DRVVBUS rw — Mux value for drvvbus if PHY_OTG_MUX_SEL_DRVVBUS=1
  [16] USB1_PHY_OTG_MUX_SEL_DRVVBUS rw — Mux select for drvvbus 0: Driven from controller 1: Use PHY_OTG_MUX_VAL_DRVVBUS
0x758 BOOTCFG_USB1_PHY_CTL2 reset 0x448CDC4
  [26:23] USB1_PHY_PC_TXVREFTUNE rw — HS DC Voltage Level Adjustment. This bus adjusts the high-speed DC level voltage. 0000: -10% 0001: -8.75% 0010: -7.5% 0011: -6.25% 0100: -5% 0101: -3.75% 0110: -2.5% 0111: -1.25% 1000: Design default 1001: +1.25% 1010: +2.5% 1011: +3.75% 1100: +5% 1101: +6.25% 1110: +7.5% 1111: +8.75%
  [22:21] USB1_PHY_PC_TXRISETUNE rw — HS Transmitter Rise/Fail Time Adjustment. This bus adjusts the rise/fail times of the high-speed waveform. 00: +20% 01: +15% 10: Design default 11: -10%
  [20:19] USB1_PHY_PC_TXRESTUNE rw — USB Source impedance Adjustment. In some applications, there can be significant series resistance on the D+ and D- paths between the transceiver and cable. This bus adjusts the driver source impedance to compensate for added series resistance on the USB. Note: Any setting other than the default can result in source impedance variation across process, voltage, and temperature conditions that does not meet USB 2.0 specification limits. 00: Source impedance is increased by approximately 1.5 ohm 01: Design default 10: Source impedance is decreased by approximately 2 ohm 11: Source impedance is decreased by approximately 4 ohm
  [18] USB1_PHY_PC_TXPREEMPPULSETUNE rw — HS Transmitter Pre-Emphasis Duration Control. This signal controls the duration for which the HS pre-emphasis current is sourced onto DP or DM. The HS Transmitter pre-emphasis duration is defined in terms of unit amounts. One unit of pre-emphasis duration is approximately 580 ps and is defined as 1X pre-emphasis duration. This signal is valid only if either TXPREEMPAMPTUNE1 or TXPREEMPAMPTUNE2 is set to 1. 0 (design default): 2X, long pre-emphasis current duration 1: 1X, short pre-emphasis current duration
  [17:16] USB1_PHY_PC_TXPREEMPAMPTUNE rw — HS Transmitter Pre-Emphasis Current Control. This signal controls the amount of current sourced to DP and after a J-to-K or K-to-J transition. The HS Transmitter pre-emphasis current is defined in terms of unit amounts. One unit amount is approximately 600 uA and is defined as 1X pre-emphasis current. 00 (design default): HS Transmitter pre-emphasis is disabled. 01: HS Transmitter pre-emphasis circuit sources 1X pre-emphasis current. 10: HS Transmitter pre-emphasis circuit sources 2X pre-emphasis current. 11: HS Transmitter pre-emphasis circuit sources 3X pre-emphasis current. If these signals are not used, set them to 00b.
  [15:14] USB1_PHY_PC_TXHSXVTUNE rw — Transmitter High-Speed Crossover Adjustment. This bus adjusts the voltage at which the DP and DM signals cross while transmitting in HS mode. 00: Reserved 01: -15mV 10: +15mV 11: Default setting
  [13:10] USB1_PHY_PC_TXFSLSTUNE rw — FS/LS Source impedance Adjustment. This bus adjusts the low- and full-speed single-ended source impedance while driving high. The following adjustment values are based on nominal process, voltage, and temperature. 0000: +5% 0001: +2.5% 0011: Design default 0111: -2.5% 1111: -5% All other bit settings are reserved.
  [9:7] USB1_PHY_PC_SQRXTUNE rw — Squelch Threshold Adjustment. This bus adjusts the voltage level for the threshold used to detect valid high-speed data. 000: +15% 001: +10% 010: +5% 011: Design default 100: -5% 101: -10% 110: -15% 111: -20%
  [6:4] USB1_PHY_PC_OTGTUNE rw — VBUS Valid Threshold Adjustment. This bus adjusts the voltage level for the VBUS valid threshold. 000: -12% 001: -9% 010: -6% 011: -3% 100: Design default 101: +3% 110: +6% 111: +9%
  [2:0] USB1_PHY_PC_COMPDISTUNE rw — Disconnect Threshold Adjustment. This bus adjusts the voltage level for the threshold used to detect a disconnect event at the host. 000: -6% 001: -4.5% 010: -3% 011: -1.5% 100: Design default 101: +1.5% 110: +3% 111: +4.5%
0x760 BOOTCFG_USB1_PHY_CTL4 reset 0x1518000
  [24:22] USB1_PHY_OSC_FSEL rw — Reference Clock Frequency Select. Selects the USB2.0 picoPHY reference clock frequency. 000: Reserved 001: Reserved 010: 12MHz 011: 19.2MHz 100: Reserved 101: 24MHz (default) 110: Reserved 111: 50MHz
  [20:19] USB1_PHY_OSC_REFCLKSEL rw — Reference Clock Select for PLL Block. This signal selects the reference clock source for the PLL Block. 00: Crystal 01: External Clock 10: Internal Clock (default) 11: Reserved
  [17] USB1_CTRL_MISC_DEBUG_EN rw — Enable CTL_MISC_DEBUG_DATA 0: disable 1: enable
  [16] USB1_PHY_OTG_VBUSVLDEXTSEL rw — External VBUS Valid Select. This signal selects either the VBUSVLDEXT input or the internal Session Valid comparator to generate the OTGSESSVLD output. To avoid potential glitches in DP, VBUSVLDEXTSEL must be static prior to a power-on reset and remain static during normal operation. The OTGSESSVLD signal, in conjunction with XCVRSEL(1:0), OPMODE(1:0), TERMSEL, DPPULLDOWN, and DMPULLDOWN, control the DP pull-up resistor. If VBUSVLDEXT and the internal Session Valid comparator output are asserted, and VBUSEXTSEL changes, it is possible for OTGSESSVLD to glitch low, causing the DP resistor to be temporarily disabled. 0: The internal Session Valid comparator is used to generate OTGSESSVLD and assert the DP pull-up resistor. 1: The VBUSVLDEXT input is used to generate OTGSESSVLD and assert the DP pull-up resistor.
  [15] USB1_PHY_OTG_OTGDISABLE rw — OTG Block Disable. This signal powers down the VBUS Valid comparator, but not the Session Valid comparator, ADP probe and sense comparators, nor the ID detection circuitry. To save power, if the application does not use the OTG function, this input can be set high. 0: The OTG block is powered up. 1: The OTG block is powered down.
0x768 BOOTCFG_USB0_EBC_IN_CTL reset 0x0
  [5:4] EBC14_SEL0 rw — 00: 1h is driven into ctrl_ebc_dev_usb0_inep_pkt_buff_avail(1) (default) 01: 1h is driven into ctrl_ebc_dev_usb0_inep_pkt_buff_avail(1) 10: ARM TBR DMA event routed to ctrl_ebc_dev_usb0_inep_pkt_buff_avail(1) 11: Debug TBR DMA event routed to ctrl_ebc_dev_usb0_inep_pkt_buff_avail(1)
  [1:0] EBC15_SEL0 rw — 00: 1h is driven into ctrl_ebc_dev_usb0_inep_pkt_buff_avail(0) (default) 01: 1h is driven into ctrl_ebc_dev_usb0_inep_pkt_buff_avail(0) 10: ARM TBR DMA event routed to ctrl_ebc_dev_usb0_inep_pkt_buff_avail(0) 11: Debug TBR DMA event routed to ctrl_ebc_dev_usb0_inep_pkt_buff_avail(0)
0x76C BOOTCFG_USB1_EBC_IN_CTL reset 0x0
  [5:4] EBC14_SEL1 rw — 00: 1h is driven into ctrl_ebc_dev_usb1_inep_pkt_buff_avail(1) (default) 01: 1h is driven into ctrl_ebc_dev_usb1_inep_pkt_buff_avail(1) 10: ARM TBR DMA event routed to ctrl_ebc_dev_usb1_inep_pkt_buff_avail(1) 11: Debug TBR DMA event routed to ctrl_ebc_dev_usb1_inep_pkt_buff_avail(1)
  [1:0] EBC15_SEL1 rw — 00: 1h is driven into ctrl_ebc_dev_usb1_inep_pkt_buff_avail(0) (default) 01: 1h is driven into ctrl_ebc_dev_usb1_inep_pkt_buff_avail(0) 10: ARM TBR DMA event routed to ctrl_ebc_dev_usb1_inep_pkt_buff_avail(0) 11: Debug TBR DMA event routed to ctrl_ebc_dev_usb1_inep_pkt_buff_avail(0)
{0x780+4i} BOOTCFG_SCRATCH{i} rw reset 0x0 (i=0..15)
  [31:0] SCRATCH
0x844 BOOTCFG_DSP_BOOT_ADDR0_NS reset 0x20B000
  [31:10] ISTP_RST_VAL rw — Non-secure boot address for C66x core
0xC80 BOOTCFG_OBSCLKCTL reset 0x100
  [18] RCOSC_OBSCLK_EN rw — This clock is not available in the current device.
  [17] HFOSC_OBSCLK_EN rw — Controls the SYS OSC observation clock enable 0 - Disable 1 - Enable
  [16] NSSPLL_OBSCLK_EN rw — Controls the NSS/IEP PLL observation clock enable 0 - Disable 1 - Enable
  [15] PLLCTL_OBSCLK_EN rw — Controls the PLL controller observation clock enable 0 - Disable 1 - Enable
  [14] DDR3APLL_OBSCLK_EN rw — Controls the DDR PLL observation clock enable 0 - Disable 1 - Enable
  [13] ICSSPLL_OBSCLK_EN rw — Controls the ICSS PLL observation clock enable 0 - Disable 1 - Enable
  [12] UARTPLL_OBSCLK_EN rw — Controls the UART PLL observation clock enable 0 - Disable 1 - Enable
  [11] ARMPLL_OBSCLK_EN rw — Controls the ARM PLL observation clock enable 0 - Disable 1 - Enable
  [10] DSSPLL_OBSCLK_EN rw — Controls the DSS PLL observation clock enable 0 - Disable 1 - Enable
  [9] MAINPLL_OBSCLK_EN rw — Controls the MAIN PLL observation clock enable 0 - Disable 1 - Enable
  [8] RSVD_OBSCLK_EN rw — This clock is not available in the current device.
  [3:0] PLL_OBSCLK_SEL rw — Controls OBSMUX to select which clock is output onto the OBSCLK[P/N] pin 0h - Reserved 1h - MAIN PLL 2h - DSS PLL 3h - ARM PLL 4h - UART PLL 5h - ICSS PLL 6h - DDR PLL 7h - PLL Controller OBSCLK 8h - NSS/IEP PLL 9h - SYS OSC clock Others - Reserved
0xC90 BOOTCFG_EFUSE_BOOTROM ro reset 0x0
  [27:16] DEVICE_SPEED — 12 EFUSE bits are allocated to indicate the device operating speed.
  [11:0] ARM_SPEED — 12 EFUSE bits are allocated to indicate the ARM operating speed.
0xD00 BOOTCFG_EVENT_MUXCTL0 rw reset 0x0
  [8n+7:8n] EVTSEL{n} (n=0..3) — Event select for Event Mux{n}
0xD04 BOOTCFG_EVENT_MUXCTL1 rw reset 0x0
  [8n-25:8n-32] EVTSEL{n} (n=4..7) — Event select for Event Mux{n}
0xD08 BOOTCFG_EVENT_MUXCTL2 rw reset 0x0
  [8n-57:8n-64] EVTSEL{n} (n=8..11) — Event select for Event Mux{n}
0xD0C BOOTCFG_EVENT_MUXCTL3 rw reset 0x0
  [8n-89:8n-96] EVTSEL{n} (n=12..15) — Event select for Event Mux{n}
0xD10 BOOTCFG_EVENT_MUXCTL4 rw reset 0x0
  [8n-121:8n-128] EVTSEL{n} (n=16..19) — Event select for Event Mux{n}
0xD14 BOOTCFG_EVENT_MUXCTL5 rw reset 0x0
  [8n-153:8n-160] EVTSEL{n} (n=20..23) — Event select for Event Mux{n}
0xD18 BOOTCFG_EVENT_MUXCTL6 rw reset 0x0
  [8n-185:8n-192] EVTSEL{n} (n=24..27) — Event select for Event Mux{n}
0xD1C BOOTCFG_EVENT_MUXCTL7 rw reset 0x0
  [8n-217:8n-224] EVTSEL{n} (n=28..31) — Event select for Event Mux{n}
0xD20 BOOTCFG_EVENT_MUXCTL8 rw reset 0x0
  [8n-249:8n-256] EVTSEL{n} (n=32..35) — Event select for Event Mux{n}
0xD24 BOOTCFG_EVENT_MUXCTL9 rw reset 0x0
  [8n-281:8n-288] EVTSEL{n} (n=36..39) — Event select for Event Mux{n}
0xD28 BOOTCFG_EVENT_MUXCTL10 rw reset 0x0
  [8n-313:8n-320] EVTSEL{n} (n=40..43) — Event select for Event Mux{n}
0xD2C BOOTCFG_EVENT_MUXCTL11 rw reset 0x0
  [8n-345:8n-352] EVTSEL{n} (n=44..47) — Event select for Event Mux{n}
0xD30 BOOTCFG_EVENT_MUXCTL12 rw reset 0x0
  [8n-377:8n-384] EVTSEL{n} (n=48..51) — Event select for Event Mux{n-4}
0xD34 BOOTCFG_EVENT_MUXCTL13 rw reset 0x0
  [8n-409:8n-416] EVTSEL{n} (n=52..55) — Event select for Event Mux{n-8}
0xE10 BOOTCFG_DCAN_RAMINIT access not given reset 0x0
  [9] DCAN1_RAMINIT_DONE — DCAN1 RAM initialization status (access RW1toC)
  [8] DCAN0_RAMINIT_DONE — DCAN0 RAM initialization status (access RW1toC)
  [1] DCAN1_RAMINIT_START — DCAN1 RAM initialization start (access RWtoPH)
  [0] DCAN0_RAMINIT_START — DCAN0 RAM initialization start (access RWtoPH)
0xE20 BOOTCFG_ETHERNET_CFG reset 0x0
  [4] RGMII_ID_MODE rw — RGMII Internal Delay Mode Selection 0h = Internal delay 1h = No internal delay
  [1:0] MODE_SEL rw — Ethernet Port Interface Mode Selection 0h = MII 1h = RMII 2h = RGMII 3h = Reserved
0xE30 BOOTCFG_MLB_SIG_IO_CTL reset 0x20 (reset mask 0x28)
  [19:16] N_TRIM rw — MLB NMOS LVDS output drive trim value
  [11:8] P_TRIM rw — MLB PMOS LVDS output drive trim value
  [5] PWRDN_RX rw — Power down control for MLB LVDS receiver 0 = Receiver is powered on 1 = Receiver is powered down
  [3] EN_EXTRES rw — Control for internal termination resistor 0h = Enable internal termination resistor 1h = Disable internal termination resistor (use external resistor)
0xE34 BOOTCFG_MLB_DAT_IO_CTL reset 0x20 (reset mask 0x28)
  fields as BOOTCFG_MLB_SIG_IO_CTL
0xE38 BOOTCFG_MLB_CLK_IO_CTL reset 0x20
  [5] PWRDN_RX rw — Power down control for MLB LVDS receiver 0 = Receiver is powered on 1 = Receiver is powered down
0xE40 BOOTCFG_EPWM_CTL reset 0x0
  [16] EPWM_EALLOW rw — EPWM trip zone and HRPWM config register writeaccess enable 0 = Disable 1 = Enable
  [13] EPWM_SOCB_SEL rw — Start of Conversion (SOCB) output source 0 = EPWM[5:0] SOCB outputs 1 = ICSS0 Host INT1
  [12] EPWM_SOCA_SEL rw — Start of Conversion (SOCA) output source 0 = EPWM[5:0] SOCA outputs 1 = ICSS0 Host INT0
  [8] EPWM3_SYNCSEL rw — EPWM3 SyncIn source 0 = EPWM3 sync is from EPWM2 (daisy chained) 1 = EPWM3 sync is from ICSS/Pin
  [n] EPWM{n}_TBCLKEN rw (n=0..5) — EPWM{n} timebase clock 0 = Disable 1 = Enable
0xE50 BOOTCFG_ECAP_CAPEVT_CTL reset 0x100
  [12:8] ECAP1_CAP_EVT rw — Select the eCAP_1 capture event
  [4:0] ECAP0_CAP_EVT rw — Select the eCAP_0 capture event
0xE60 BOOTCFG_EQEP_STAT ro reset 0x0
  [2] PHASE_ERR2 — EQEP2 phase error status 0 = No error 1 = Phase error
  [1] PHASE_ERR1 — EQEP1 phase error status 0 = No error 1 = Phase error
  [0] PHASE_ERR0 — EQEP0 phase error status 0 = No error 1 = Phase error
0xE70 BOOTCFG_LVDS_BG_CTL reset 0x0 (reset mask 0x88)
  [7] LVDS1_PWRDN_BG rw — Power down control for the LVDS1 bandgap buffer
  [6] LVDS1_TRIM_EN rw — LVDS1 bandgap trim enable. When set high, LVDS1_TRIM bits are used
  [5:4] LVDS1_TRIM rw — LVDS1 bandgap trim input, vbias trims for CPTS_REFCLK, MLBP_SIG, MLBP_DAT and MLBP_CLK.
  [3] LVDS0_PWRDN_BG rw — Power down control for the LVDS0 bandgap buffer
  [2] LVDS0_TRIM_EN rw — LVDS0 bandgap trim enable. When set high, LVDS0_TRIM bits are used.
  [1:0] LVDS0_TRIM rw — LVDS0 bandgap trim input, vbias trims for DDR_CLK and SYSCLK.
0xE80 BOOTCFG_LDO_USB_CTL
  [25:16] VSET rw — Used to program the output voltage (vddar) of GPLDOBG (General Purpose Low Drop Output with integrated BandGap)
  [4:0] BGAP_TRIM rw — BandGap reference magnitude trim. Requires efuse trim
0xE84 BOOTCFG_LDO_PCIE_CTL
  fields as BOOTCFG_LDO_USB_CTL
{0x1000+4i} BOOTCFG_PADCONFIG{i} (i=0..258)
  [20:19] BUFFERCLASS rw — Buffer class selection (CS1, CS0) For 3.3V I/Os: 0h and 1h - 50B 50 ohm nominal impedance for the buffer, class B driver 100MHz in 50 ohm mode 2h and 3h - 40D 40 ohm nominal impedance for the buffer, class D driver 200MHz in 40 ohm mode For 1.8V I/Os: 0h - 50B 50 ohm nominal impedance for the buffer, class B driver 100MHz in 50 ohm mode 1h - 40C 40 ohm nominal impedance for the buffer, class C driver 150MHz in 40 ohm mode 2h - 40D 40 ohm nominal impedance for the buffer, class D driver 200MHz in 40 ohm mode 3h - 40E 40 ohm nominal impedance for the buffer, class E driver 250MHz in 40 ohm mode
  [18] RESERVED rw — This bit must not be modified.
  [17] PULLTYPESEL rw — Pull-up or pull-down resistor selection 0h - Pull-down is selected 1h - Pull-up is selected
  [16] PULLUDEN rw — Pull-up/pull-down resistor enable 0h - Pull-up/pull-down enabled 1h - Pull-up/pull-down disabled
  [3:0] MUXMODE rw — Pad functional signal mux selection 0h - Primary function 1h - Secondary function 2h - Tertiary function 3h - Quaternary function 4h - Quinary function 5h - Senary function
